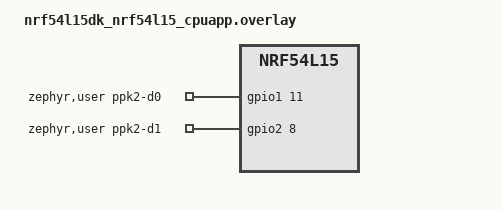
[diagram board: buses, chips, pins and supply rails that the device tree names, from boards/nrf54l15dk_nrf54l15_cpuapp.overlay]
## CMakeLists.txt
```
# SPDX-License-Identifier: Apache-2.0 OR MIT
cmake_minimum_required(VERSION 3.20.0)
find_package(Zephyr REQUIRED HINTS $ENV{ZEPHYR_BASE})
project(ble_advertising LANGUAGES C)

target_sources(app PRIVATE src/main.c)
```

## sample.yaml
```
sample:
  name: PPK2 markers on a BLE advertiser
  description: Radio activity on D0 by hardware, a sensor read on D1
tests:
  sample.ppk2.ble_advertising:
    platform_allow:
      - nrf54lm20dk/nrf54lm20b/cpuapp
      - nrf54l15dk/nrf54l15/cpuapp
    tags: ppk2 power bluetooth
    build_only: true
```

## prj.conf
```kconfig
CONFIG_BT=y
CONFIG_BT_BROADCASTER=y

CONFIG_GPIO=y
CONFIG_PPK2_TRACE=y
CONFIG_PPK2_TRACE_RADIO=y
CONFIG_PPK2_TRACE_RADIO_CHANNEL=0

# Nothing but the application shapes the current.
CONFIG_LOG=n
CONFIG_PRINTK=n
CONFIG_BOOT_BANNER=n
CONFIG_CONSOLE=n
CONFIG_SERIAL=n
CONFIG_UART_CONSOLE=n
```

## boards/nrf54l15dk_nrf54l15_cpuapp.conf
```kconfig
# This kit is on the board list of the SDK's option for radio pins: the
# SDK drives D0, and the module only names the channel.
CONFIG_MPSL_PIN_DEBUG=y
```

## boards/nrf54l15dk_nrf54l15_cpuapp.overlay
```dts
/* SPDX-License-Identifier: Apache-2.0 OR MIT */
/ {
	zephyr,user {
		/* P1.11 is the pin that CONFIG_MPSL_PIN_DEBUG drives by default. */
		ppk2-d0-gpios = <&gpio1 11 GPIO_ACTIVE_HIGH>;
		ppk2-d1-gpios = <&gpio2 8 GPIO_ACTIVE_HIGH>;
	};
};
```

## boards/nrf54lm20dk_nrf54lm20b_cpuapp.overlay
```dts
/* SPDX-License-Identifier: Apache-2.0 OR MIT */
/ {
	zephyr,user {
		ppk2-d0-gpios = <&gpio1 12 GPIO_ACTIVE_HIGH>;
		ppk2-d1-gpios = <&gpio1 13 GPIO_ACTIVE_HIGH>;
	};
};
```

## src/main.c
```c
/*
 * SPDX-License-Identifier: Apache-2.0 OR MIT
 *
 * A BLE advertiser that reads a sensor once a second and puts the value
 * in its advertising data. D0 is the radio, raised by hardware
 * (CONFIG_PPK2_TRACE_RADIO). D1 is the sensor read, a 5 ms busy wait
 * that stands in for one.
 */
#include <zephyr/bluetooth/bluetooth.h>
#include <zephyr/kernel.h>

#include <ppk2_trace.h>

PPK2_TRACE_CLAIM(1, sensor);

static uint8_t reading[] = {0xff, 0xff, 0x00}; /* manufacturer data: test company ID, value */

static const struct bt_data ad[] = {
	BT_DATA_BYTES(BT_DATA_FLAGS, BT_LE_AD_NO_BREDR),
	BT_DATA(BT_DATA_MANUFACTURER_DATA, reading, sizeof(reading)),
};

static void read_sensor(void)
{
	PPK2_TRACE_SCOPE(ppk2_ch_sensor);

	k_busy_wait(5000);
	reading[2]++;
}

int main(void)
{
	if (bt_enable(NULL) != 0 ||
	    bt_le_adv_start(BT_LE_ADV_NCONN, ad, ARRAY_SIZE(ad), NULL, 0) != 0) {
		return 0;
	}
	while (1) {
		k_sleep(K_SECONDS(1));
		read_sensor();
		bt_le_adv_update_data(ad, ARRAY_SIZE(ad), NULL, 0);
	}
	return 0;
}
```
